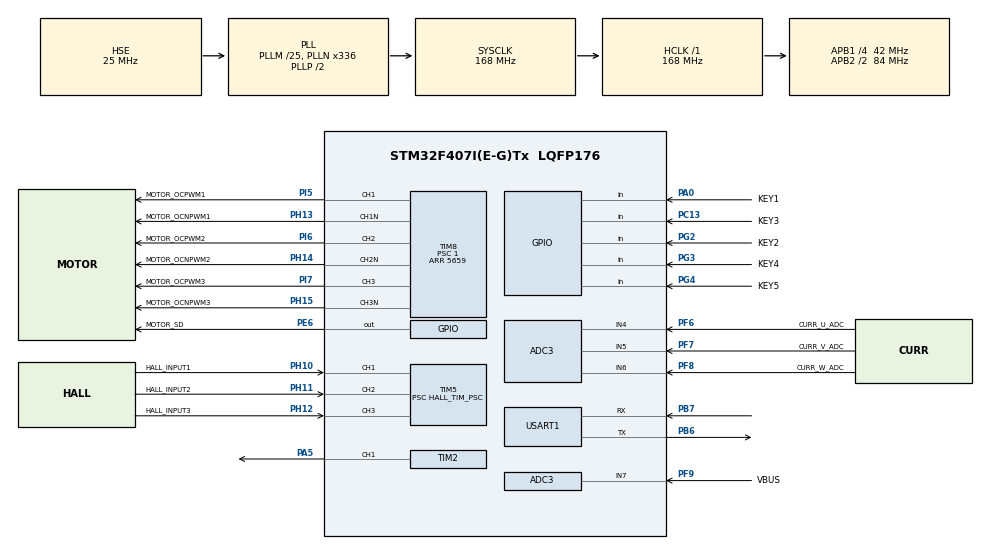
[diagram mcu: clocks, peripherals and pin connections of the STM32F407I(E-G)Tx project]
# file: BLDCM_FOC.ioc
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ADC3.Channel-0\#ChannelRegularConversion=ADC_CHANNEL_4
ADC3.Channel-5\#ChannelInjectedConversion=ADC_CHANNEL_4
ADC3.Channel-6\#ChannelInjectedConversion=ADC_CHANNEL_5
ADC3.Channel-7\#ChannelInjectedConversion=ADC_CHANNEL_6
ADC3.Channel-8\#ChannelInjectedConversion=ADC_CHANNEL_7
ADC3.ContinuousConvMode=ENABLE
ADC3.DMAContinuousRequests=DISABLE
ADC3.EOCSelection=ADC_EOC_SINGLE_CONV
ADC3.ExternalTrigConv=ADC_SOFTWARE_START
ADC3.ExternalTrigInjecConv=ADC_EXTERNALTRIGINJECCONV_T2_CC1
ADC3.InjNumberOfConversion=4
ADC3.InjectedOffset-5\#ChannelInjectedConversion=0
ADC3.InjectedOffset-6\#ChannelInjectedConversion=0
ADC3.InjectedOffset-7\#ChannelInjectedConversion=0
ADC3.InjectedOffset-8\#ChannelInjectedConversion=0
ADC3.InjectedRank-5\#ChannelInjectedConversion=1
ADC3.InjectedRank-6\#ChannelInjectedConversion=2
ADC3.InjectedRank-7\#ChannelInjectedConversion=3
ADC3.InjectedRank-8\#ChannelInjectedConversion=4
ADC3.NbrOfConversion=1
ADC3.NbrOfConversionFlag=1
ADC3.Rank-0\#ChannelRegularConversion=1
ADC3.SamplingTime-0\#ChannelRegularConversion=ADC_SAMPLETIME_3CYCLES
ADC3.SamplingTime-5\#ChannelInjectedConversion=ADC_SAMPLETIME_3CYCLES
ADC3.SamplingTime-6\#ChannelInjectedConversion=ADC_SAMPLETIME_3CYCLES
ADC3.SamplingTime-7\#ChannelInjectedConversion=ADC_SAMPLETIME_3CYCLES
ADC3.SamplingTime-8\#ChannelInjectedConversion=ADC_SAMPLETIME_3CYCLES
ADC3.ScanConvMode=ENABLE
Mcu.Family=STM32F4
Mcu.Name=STM32F407I(E-G)Tx
Mcu.Package=LQFP176
Mcu.UserConstants=HALL_TIM_PSC,167;HALL_TIM_Counter,4999;ADC_TIM_PSC,167;ADC_TIM_Counter,4999;PWM_TIM_PSC,1;PWM_TIM_Counter,5659
NVIC.ADC_IRQn=true\:0\:0\:false\:false\:true\:true\:true
NVIC.PriorityGroup=NVIC_PRIORITYGROUP_4
NVIC.TIM5_IRQn=true\:0\:0\:false\:false\:true\:true\:true
NVIC.USART1_IRQn=true\:3\:0\:true\:false\:true\:true\:true
PA0-WKUP.GPIO_Label=KEY1
PA0-WKUP.Signal=GPIO_Input
PA5.Signal=S_TIM2_CH1_ETR
PB6.Mode=Asynchronous
PB6.Signal=USART1_TX
PB7.Mode=Asynchronous
PB7.Signal=USART1_RX
PC13-ANTI_TAMP.GPIO_Label=KEY3
PC13-ANTI_TAMP.Signal=GPIO_Input
PE6.GPIO_Label=MOTOR_SD
PE6.GPIO_Speed=GPIO_SPEED_FREQ_HIGH
PE6.Signal=GPIO_Output
PF6.GPIO_Label=CURR_U_ADC
PF6.Mode=IN4
PF6.Signal=ADC3_IN4
PF7.GPIO_Label=CURR_V_ADC
PF7.Mode=IN5
PF7.Signal=ADC3_IN5
PF8.GPIO_Label=CURR_W_ADC
PF8.Mode=IN6
PF8.Signal=ADC3_IN6
PF9.GPIO_Label=VBUS
PF9.Mode=IN7
PF9.Signal=ADC3_IN7
PG2.GPIO_Label=KEY2
PG2.Signal=GPIO_Input
PG3.GPIO_Label=KEY4
PG3.Signal=GPIO_Input
PG4.GPIO_Label=KEY5
PG4.Signal=GPIO_Input
PH0-OSC_IN.Mode=HSE-External-Oscillator
PH0-OSC_IN.Signal=RCC_OSC_IN
PH1-OSC_OUT.Mode=HSE-External-Oscillator
PH1-OSC_OUT.Signal=RCC_OSC_OUT
PH10.GPIO_Label=HALL_INPUT1
PH10.GPIO_Speed=GPIO_SPEED_FREQ_HIGH
PH10.Signal=S_TIM5_CH1
PH11.GPIO_Label=HALL_INPUT2
PH11.GPIO_Speed=GPIO_SPEED_FREQ_HIGH
PH11.Signal=S_TIM5_CH2
PH12.GPIO_Label=HALL_INPUT3
PH12.GPIO_Speed=GPIO_SPEED_FREQ_HIGH
PH12.Signal=S_TIM5_CH3
PH13.GPIO_Label=MOTOR_OCNPWM1
PH13.GPIO_Speed=GPIO_SPEED_FREQ_HIGH
PH13.Mode=PWM Generation1 CH1 CH1N
PH13.Signal=TIM8_CH1N
PH14.GPIO_Label=MOTOR_OCNPWM2
PH14.GPIO_Speed=GPIO_SPEED_FREQ_HIGH
PH14.Mode=PWM Generation2 CH2 CH2N
PH14.Signal=TIM8_CH2N
PH15.GPIO_Label=MOTOR_OCNPWM3
PH15.GPIO_Speed=GPIO_SPEED_FREQ_HIGH
PH15.Mode=PWM Generation3 CH3 CH3N
PH15.Signal=TIM8_CH3N
PI5.GPIO_Label=MOTOR_OCPWM1
PI5.GPIO_Speed=GPIO_SPEED_FREQ_HIGH
PI5.Signal=S_TIM8_CH1
PI6.GPIO_Label=MOTOR_OCPWM2
PI6.GPIO_Speed=GPIO_SPEED_FREQ_HIGH
PI6.Signal=S_TIM8_CH2
PI7.GPIO_Label=MOTOR_OCPWM3
PI7.GPIO_Speed=GPIO_SPEED_FREQ_HIGH
PI7.Signal=S_TIM8_CH3
ProjectManager.HeapSize=0x200
ProjectManager.StackSize=0x400
ProjectManager.TargetToolchain=MDK-ARM V5.27
RCC.48MHZClocksFreq_Value=84000000
RCC.AHBFreq_Value=168000000
RCC.APB1CLKDivider=RCC_HCLK_DIV4
RCC.APB1Freq_Value=42000000
RCC.APB1TimFreq_Value=84000000
RCC.APB2CLKDivider=RCC_HCLK_DIV2
RCC.APB2Freq_Value=84000000
RCC.APB2TimFreq_Value=168000000
RCC.CortexFreq_Value=168000000
RCC.HCLKFreq_Value=168000000
RCC.HSE_VALUE=25000000
RCC.HSI_VALUE=16000000
RCC.LSE_VALUE=32768
RCC.PLLM=25
RCC.PLLN=336
RCC.PLLSourceVirtual=RCC_PLLSOURCE_HSE
RCC.SYSCLKFreq_VALUE=168000000
RCC.SYSCLKSource=RCC_SYSCLKSOURCE_PLLCLK
RCC.VCOOutputFreq_Value=336000000
SH.S_TIM2_CH1_ETR.0=TIM2_CH1,PWM Generation1 CH1
SH.S_TIM5_CH1.0=TIM5_CH1,Xored_Inputs_Hall_Sensor_Interface
SH.S_TIM5_CH2.0=TIM5_CH2,Xored_Inputs_Hall_Sensor_Interface
SH.S_TIM5_CH3.0=TIM5_CH3,Xored_Inputs_Hall_Sensor_Interface
SH.S_TIM8_CH1.0=TIM8_CH1,PWM Generation1 CH1 CH1N
SH.S_TIM8_CH2.0=TIM8_CH2,PWM Generation2 CH2 CH2N
SH.S_TIM8_CH3.0=TIM8_CH3,PWM Generation3 CH3 CH3N
TIM2.Channel-PWM\ Generation1\ CH1=TIM_CHANNEL_1
TIM2.Period=ADC_TIM_Counter
TIM2.Prescaler=ADC_TIM_PSC
TIM2.TIM_MasterOutputTrigger=TIM_TRGO_OC2REF
TIM2.TIM_MasterSlaveMode=TIM_MASTERSLAVEMODE_ENABLE
TIM5.IC1Filter=10
TIM5.IC1Polarity=TIM_ICPOLARITY_RISING
TIM5.Period=HALL_TIM_Counter
TIM5.Prescaler=HALL_TIM_PSC
TIM8.Channel-PWM\ Generation1\ CH1\ CH1N=TIM_CHANNEL_1
TIM8.Channel-PWM\ Generation2\ CH2\ CH2N=TIM_CHANNEL_2
TIM8.Channel-PWM\ Generation3\ CH3\ CH3N=TIM_CHANNEL_3
TIM8.Channel-PWM\ Generation4\ No\ Output=TIM_CHANNEL_4
TIM8.CounterMode=TIM_COUNTERMODE_CENTERALIGNED1
TIM8.OCIdleState_1=TIM_OCIDLESTATE_SET
TIM8.OCIdleState_2=TIM_OCIDLESTATE_SET
TIM8.OCIdleState_3=TIM_OCIDLESTATE_SET
TIM8.Period=5659
TIM8.Prescaler=1
USART1.VirtualMode=VM_ASYNC
VP_TIM2_VS_ClockSourceINT.Mode=Internal
VP_TIM8_VS_ClockSourceITR.Mode=TriggerSource_ITR1
VP_TIM8_VS_ControllerModeTrigger.Mode=Trigger Mode
VP_TIM8_VS_no_output4.Mode=PWM Generation4 No Output
board=custom

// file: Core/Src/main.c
/* USER CODE BEGIN Header */
/**
 ******************************************************************************
 * @file           : main.c
 * @brief          : Main program body
 ******************************************************************************
 * @attention
 *
 * <h2><center>&copy; Copyright (c) 2023 STMicroelectronics.
 * All rights reserved.</center></h2>
 *
 * This software component is licensed by ST under BSD 3-Clause license,
 * the "License"; You may not use this file except in compliance with the
 * License. You may obtain a copy of the License at:
 *                        opensource.org/licenses/BSD-3-Clause
 *
 ******************************************************************************
 */
/* USER CODE END Header */
#include "main.h"
#include "adc.h"
#include "tim.h"
#include "usart.h"
#include "gpio.h"

/* USER CODE BEGIN Includes */

#include "bldcm_control.h"
#include <stdio.h>

/* USER CODE END Includes */

void SystemClock_Config(void);

int main(void)
{

  /* MCU Configuration--------------------------------------------------------*/

  /* Reset of all peripherals, Initializes the Flash interface and the Systick. */
  HAL_Init();

  /* Configure the system clock */
  SystemClock_Config();

  /* Initialize all configured peripherals */
  MX_GPIO_Init();
  MX_USART1_UART_Init();
  MX_TIM5_Init();
  MX_TIM8_Init();
  MX_ADC3_Init();
  MX_TIM2_Init();
  /* USER CODE BEGIN 2 */

    printf("Hello World\n");
    init();
  /* USER CODE END 2 */

  /* Infinite loop */
  /* USER CODE BEGIN WHILE */
    while (1) {
		  loop();
    /* USER CODE END WHILE */

    }
}

void SystemClock_Config(void)
{
  RCC_OscInitTypeDef RCC_OscInitStruct = {0};
  RCC_ClkInitTypeDef RCC_ClkInitStruct = {0};

  /** Configure the main internal regulator output voltage
  */
  __HAL_RCC_PWR_CLK_ENABLE();
  __HAL_PWR_VOLTAGESCALING_CONFIG(PWR_REGULATOR_VOLTAGE_SCALE1);
  /** Initializes the RCC Oscillators according to the specified parameters
  * in the RCC_OscInitTypeDef structure.
  */
  RCC_OscInitStruct.OscillatorType = RCC_OSCILLATORTYPE_HSE;
  RCC_OscInitStruct.HSEState = RCC_HSE_ON;
  RCC_OscInitStruct.PLL.PLLState = RCC_PLL_ON;
  RCC_OscInitStruct.PLL.PLLSource = RCC_PLLSOURCE_HSE;
  RCC_OscInitStruct.PLL.PLLM = 25;
  RCC_OscInitStruct.PLL.PLLN = 336;
  RCC_OscInitStruct.PLL.PLLP = RCC_PLLP_DIV2;
  RCC_OscInitStruct.PLL.PLLQ = 4;
  if (HAL_RCC_OscConfig(&RCC_OscInitStruct) != HAL_OK)
  {
    Error_Handler();
  }
  /** Initializes the CPU, AHB and APB buses clocks
  */
  RCC_ClkInitStruct.ClockType = RCC_CLOCKTYPE_HCLK|RCC_CLOCKTYPE_SYSCLK
                              |RCC_CLOCKTYPE_PCLK1|RCC_CLOCKTYPE_PCLK2;
  RCC_ClkInitStruct.SYSCLKSource = RCC_SYSCLKSOURCE_PLLCLK;
  RCC_ClkInitStruct.AHBCLKDivider = RCC_SYSCLK_DIV1;
  RCC_ClkInitStruct.APB1CLKDivider = RCC_HCLK_DIV4;
  RCC_ClkInitStruct.APB2CLKDivider = RCC_HCLK_DIV2;

  if (HAL_RCC_ClockConfig(&RCC_ClkInitStruct, FLASH_LATENCY_5) != HAL_OK)
  {
    Error_Handler();
  }
}

void Error_Handler(void)
{
  /* USER CODE BEGIN Error_Handler_Debug */
    /* User can add his own implementation to report the HAL error return state */
    printf("ERROR!!!");
  /* USER CODE END Error_Handler_Debug */
}

/************************ (C) COPYRIGHT STMicroelectronics *****END OF FILE****/
